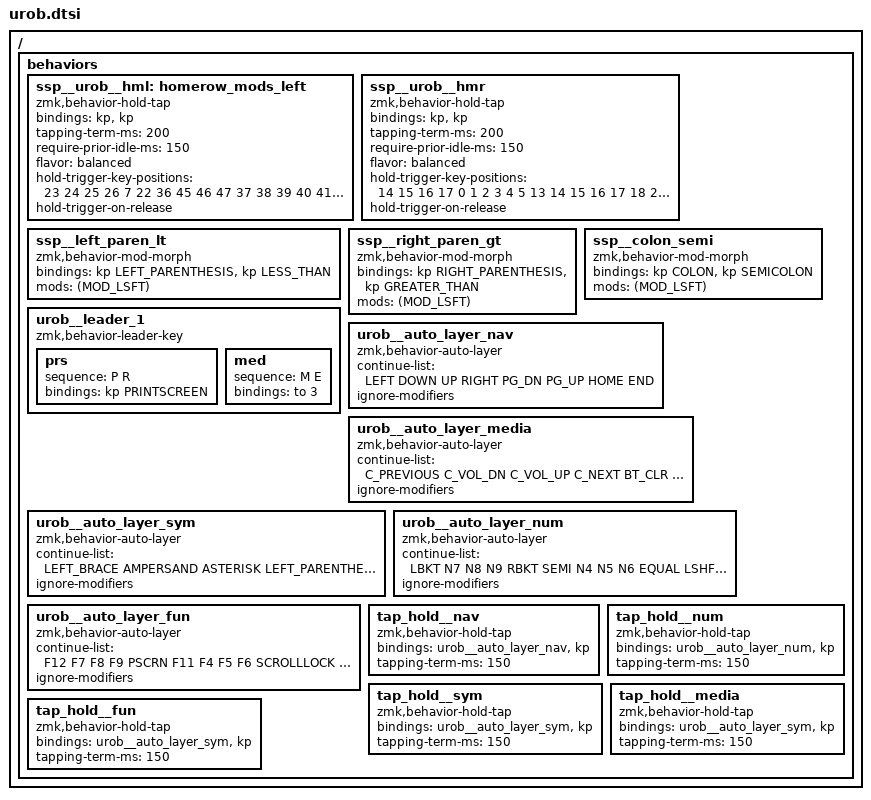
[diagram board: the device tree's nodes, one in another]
/ {
    behaviors {        ssp__urob__hml: homerow_mods_left {
            compatible = "zmk,behavior-hold-tap";
            bindings = <&kp>, <&kp>;

            #binding-cells = <2>;
            tapping-term-ms = <200>;
            require-prior-idle-ms = <150>;
            flavor = "balanced";
            hold-trigger-key-positions = <23 24 25 26 7 22 36 45 46 47 37 38 39 40 41 8 9 10 11 12 23 24 25 26 27 42 43 44>;
            hold-trigger-on-release;
        };

        ssp__urob__hmr: ssp__urob__hmr {
            compatible = "zmk,behavior-hold-tap";
            bindings = <&kp>, <&kp>;

            #binding-cells = <2>;
            tapping-term-ms = <200>;
            require-prior-idle-ms = <150>;
            flavor = "balanced";
            hold-trigger-key-positions = <14 15 16 17 0 1 2 3 4 5 13 14 15 16 17 18 28 29 30 31 32 33 42 43 44 45 46 47>;
            hold-trigger-on-release;
        };

        ssp__left_paren_lt: ssp__left_paren_lt {
            compatible = "zmk,behavior-mod-morph";
            bindings = <&kp LEFT_PARENTHESIS>, <&kp LESS_THAN>;

            #binding-cells = <0>;
            mods = <(MOD_LSFT)>;
        };

        ssp__right_paren_gt: ssp__right_paren_gt {
            compatible = "zmk,behavior-mod-morph";
            bindings = <&kp RIGHT_PARENTHESIS>, <&kp GREATER_THAN>;

            #binding-cells = <0>;
            mods = <(MOD_LSFT)>;
        };

        ssp__colon_semi: ssp__colon_semi {
            compatible = "zmk,behavior-mod-morph";
            bindings = <&kp COLON>, <&kp SEMICOLON>;

            #binding-cells = <0>;
            mods = <(MOD_LSFT)>;
        };

        urob__leader_1: urob__leader_1 {
            compatible = "zmk,behavior-leader-key";
            #binding-cells = <0>;

            prs {
                sequence = <P R>;
                bindings = <&kp PRINTSCREEN>;
            };

            med {
                sequence = <M E>;
                bindings = <&to 3>;
            };
        };

        urob__auto_layer_nav: urob__auto_layer_nav {
            compatible = "zmk,behavior-auto-layer";
            #binding-cells = <1>;
            continue-list = <LEFT DOWN UP RIGHT PG_DN PG_UP HOME END>;
            ignore-modifiers;
        };

        urob__auto_layer_media: urob__auto_layer_media {
            compatible = "zmk,behavior-auto-layer";
            #binding-cells = <1>;
            continue-list = <C_PREVIOUS C_VOL_DN C_VOL_UP C_NEXT BT_CLR BT_SEL 0 BT_SEL 1 BT_SEL 2 BT_SEL 3 BT_SEL 4 C_STOP C_PLAY_PAUSE C_MUTE>;
            ignore-modifiers;
        };

        urob__auto_layer_sym: urob__auto_layer_sym {
            compatible = "zmk,behavior-auto-layer";
            #binding-cells = <1>;
            continue-list = <LEFT_BRACE AMPERSAND ASTERISK LEFT_PARENTHESIS RIGHT_BRACE COLON DOLLAR PERCENT CARET PLUS LSHFT LCTRL LALT LGUI TILDE EXCLAMATION AT_SIGN HASH PIPE LEFT_PARENTHESIS RIGHT_PARENTHESIS UNDERSCORE>;
            ignore-modifiers;
        };

        urob__auto_layer_num: urob__auto_layer_num {
            compatible = "zmk,behavior-auto-layer";
            #binding-cells = <1>;
            continue-list = <LBKT N7 N8 N9 RBKT SEMI N4 N5 N6 EQUAL LSHFT LCTRL LALT LGUI GRAVE N1 N2 N3 BSLH PERIOD N0 MINUS>;
            ignore-modifiers;
        };

        urob__auto_layer_fun: urob__auto_layer_fun {
            compatible = "zmk,behavior-auto-layer";
            #binding-cells = <1>;
            continue-list = <F12 F7 F8 F9 PSCRN F11 F4 F5 F6 SCROLLLOCK LSHFT LCTRL LALT LGUI F10 F1 F2 F3 PAUSE_BREAK C_MENU SPACE TAB>;
            ignore-modifiers;
        };

        tap_hold__nav: tap_hold__nav {
            compatible = "zmk,behavior-hold-tap";
            bindings = <&urob__auto_layer_nav>, <&kp>;

            #binding-cells = <2>;
            tapping-term-ms = <150>;
        };

        tap_hold__num: tap_hold__num {
            compatible = "zmk,behavior-hold-tap";
            bindings = <&urob__auto_layer_num>, <&kp>;

            #binding-cells = <2>;
            tapping-term-ms = <150>;
        };

        tap_hold__sym: tap_hold__sym {
            compatible = "zmk,behavior-hold-tap";
            bindings = <&urob__auto_layer_sym>, <&kp>;

            #binding-cells = <2>;
            tapping-term-ms = <150>;
        };

        tap_hold__media: tap_hold__media {
            compatible = "zmk,behavior-hold-tap";
            bindings = <&urob__auto_layer_sym>, <&kp>;

            #binding-cells = <2>;
            tapping-term-ms = <150>;
        };

        tap_hold__fun: tap_hold__fun {
            compatible = "zmk,behavior-hold-tap";
            bindings = <&urob__auto_layer_sym>, <&kp>;

            #binding-cells = <2>;
            tapping-term-ms = <150>;
        };        };
        };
